# STM32H7R register map
File version: 1.3
CPU: CM7 r0p1, little endian, MPU, FPU, 4 interrupt priority bits
Registers are 32-bit, read-write, reset 0x0 unless marked. A register's access mark holds for its fields unless they carry their own. Offsets are from the block's base; [hi:lo] are bit positions; {n}, {i} and the like mark numbered series.

## DBGMCU — Microcontroller debug unit
Base 0x5C001000
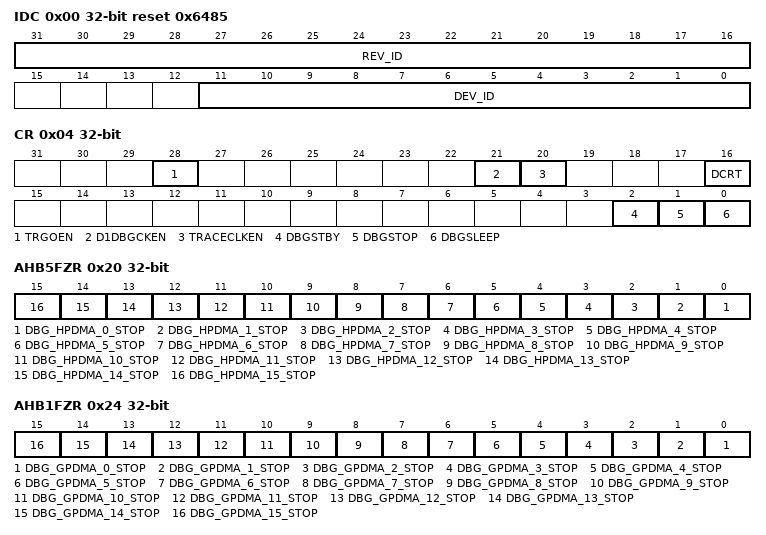
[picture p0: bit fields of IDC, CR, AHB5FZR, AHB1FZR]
0x00 IDC ro reset 0x6485 (reset mask 0xFFFF) — DBGMCU identity code register
  [31:16] REV_ID — Revision
  [11:0] DEV_ID — Device ID
0x04 CR — DBGMCU configuration register
  [28] TRGOEN — External trigger output enable This bit controls the direction of the bi-directional trigger pin, TRGIO.
  [21] D1DBGCKEN — D1 debug clock enable This bit allows the debug components in the D1 clock domain (excluding those in the processor core) to be switched off if they are not needed.
  [20] TRACECLKEN — Trace port clock enable. This bit enables the trace port clock, TRACECLK.
  [16] DCRT — Debug credentials reset type This bit selects which type of reset is used to revoke the debug authentication credentials
  [2] DBGSTBY — Debug in Standby mode enable
  [1] DBGSTOP — Debug in Stop mode enable
  [0] DBGSLEEP — Debug in Sleep mode enable
0x20 AHB5FZR — DBGMCU AHB5 peripheral freeze register
  [n] DBG_HPDMA_{n}_STOP (n=0..15) — HPDMA channel {n} stop in debug
0x24 AHB1FZR — DBGMCU AHB1 peripheral freeze register
  [n] DBG_GPDMA_{n}_STOP (n=0..15) — GPDMA channel {n} stop in debug
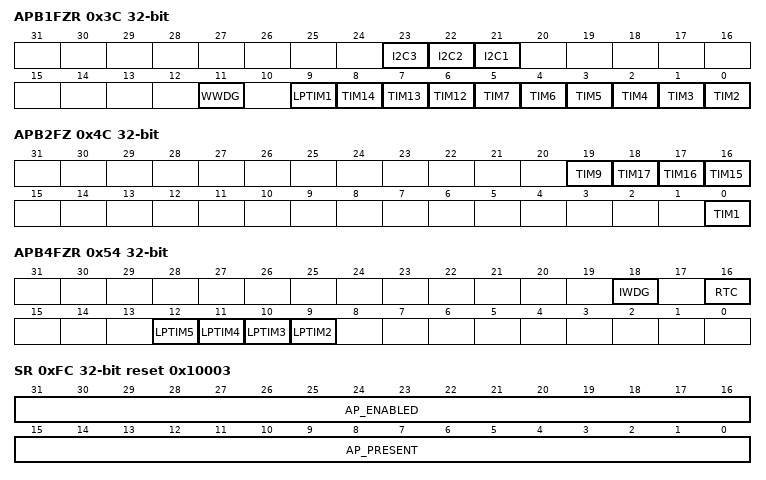
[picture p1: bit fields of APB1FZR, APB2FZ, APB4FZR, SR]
0x3C APB1FZR — DBGMCU APB1 peripheral freeze register
  [23] I2C3 — I2C3 SMBUS timeout stop in debug
  [22] I2C2 — I2C2 SMBUS timeout stop in debug
  [21] I2C1 — I2C1 SMBUS timeout stop in debug
  [11] WWDG — WWDG stop in debug
  [9] LPTIM1 — LPTIM1 stop in debug
  [8] TIM14 — TIM14 stop in debug
  [7] TIM13 — TIM13 stop in debug
  [6] TIM12 — TIM12 stop in debug
  [n-2] TIM{n} (n=2..7) — TIM{n} stop in debug
0x4C APB2FZ — DBGMCU APB2 peripheral freeze register
  [19] TIM9 — TIM9 stop in debug
  [18] TIM17 — TIM17 stop in debug
  [17] TIM16 — TIM16 stop in debug
  [16] TIM15 — TIM15 stop in debug
  [0] TIM1 — TIM1 stop in debug
0x54 APB4FZR — DBGMCU APB4 peripheral freeze register
  [18] IWDG — Independent watchdog for stop in debug
  [16] RTC — RTC stop in debug
  [12] LPTIM5 — LPTIM5 stop in debug
  [11] LPTIM4 — LPTIM4 stop in debug
  [10] LPTIM3 — LPTIM2 stop in debug
  [9] LPTIM2 — LPTIM2 stop in debug
0xFC SR ro reset 0x10003 — DBGMCU status register
  [31:16] AP_ENABLED — Bit n identifies whether access port AP n is open (can be accessed via the debug port) or locked (debug access to the AP is blocked) Bit n = 0: APn locked Bit n = 1: APn enabled
  [15:0] AP_PRESENT — Bit n identifies whether access port AP n is open (can be accessed via the debug port) or locked (debug access to the AP is blocked) Bit n = 0: APn absent Bit n = 1: APn present
0x100 DBG_AUTH_HOST reset not defined — DBGMCU debug authentication mailbox host register
  [31:0] MESSAGE — Debug host to device mailbox message. During debug authentication the debug host communicates with the device via this register.
0x104 DBG_AUTH_DEVICE reset not defined — DBGMCU debug authentication mailbox device register
  [31:0] MESSAGE — Device to debug host mailbox message. During debug authentication the device communicates with the debug host via this register.
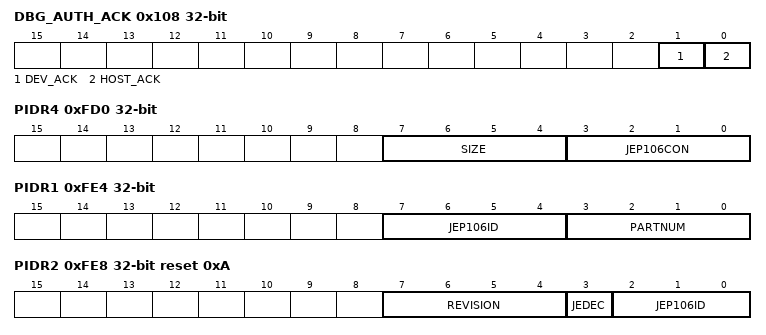
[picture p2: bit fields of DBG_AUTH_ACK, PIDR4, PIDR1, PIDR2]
0x108 DBG_AUTH_ACK — DBGMCU debug authentication mailbox acknowledge register
  [1] DEV_ACK — Device to device acknowledge. The host sets this bit to indicate that it has placed a message in the DBGMCU_DBG_AUTH_HOST register. It is reset by the device after reading the message
  [0] HOST_ACK — Host to device acknowledge. The device sets this bit to indicate that it has placed a message in the DBGMCU_DBG_AUTH_DEVICE register. It should be reset by the host after reading the message
0xFD0 PIDR4 ro — DBGMCU peripheral identity register 4
  [7:4] SIZE — Register file size
  [3:0] JEP106CON — JEP106 continuation code
0xFE0 PIDR0 ro — DBGMCU peripheral identity register 0
  [7:0] PARTNUM — Part number field, bits [7:0]
0xFE4 PIDR1 ro — DBGMCU peripheral identity register 1
  [7:4] JEP106ID — JEP106 identity code field, bits [3:0]
  [3:0] PARTNUM — Part number field, bits [11:8]
0xFE8 PIDR2 ro reset 0xA — DBGMCU peripheral identity register 2
  [7:4] REVISION — Component revision number
  [3] JEDEC — JEDEC assigned value
  [2:0] JEP106ID — JEP106 identity code field, bits [6:4]
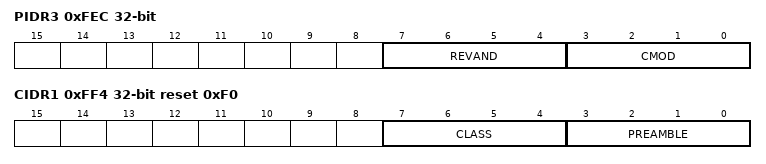
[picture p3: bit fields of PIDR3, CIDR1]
0xFEC PIDR3 ro — DBGMCU peripheral identity register 3
  [7:4] REVAND — Metal fix version
  [3:0] CMOD — Customer modified
0xFF0 CIDR0 ro reset 0xD — DBGMCU component identity register
  [7:0] PREAMBLE — Component ID field, bits [7:0]
0xFF4 CIDR1 ro reset 0xF0 — DBGMCU component identity register
  [7:4] CLASS — Component ID field, bits [15:12] - component class
  [3:0] PREAMBLE — Component ID field, bits [11:8]
0xFF8 CIDR2 ro reset 0x5 — DBGMCU component identity register
  [7:0] PREAMBLE — Component ID field, bits [23:16]
0xFFC CIDR3 ro reset 0xB1 — DBGMCU component identity register
  [7:0] PREAMBLE — Component ID field, bits [31:24]
